# ADSP-2183xW_HPC register map
Vendor: Analog Devices; Series: ADSP-2183xW_HPC; File version: 3.0.3.517
CPU: 
Registers are 32-bit, read-write, reset 0x0 unless marked. A register's access mark holds for its fields unless they carry their own. Offsets are from the block's base; [hi:lo] are bit positions; {n}, {i} and the like mark numbered series.

## PDM0 — Pulse Density Modulation interface block
Base 0x310C9000
Same registers: PDM1 0x310CA000
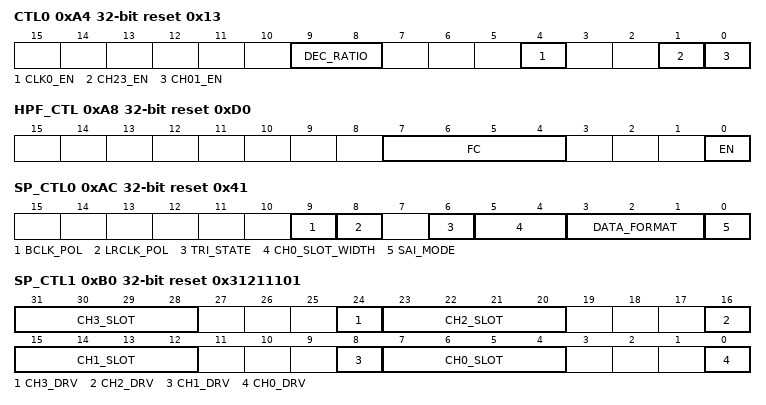
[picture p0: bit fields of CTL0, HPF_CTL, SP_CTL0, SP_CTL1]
0xA4 CTL0 reset 0x13 — PDM Control Register
  [9:8] DEC_RATIO — Decimation Ratio
    0=SIXFOUR (64 times decimation); 1=THREETWO (32 times decimation); 2=ONESIX (16 times decimation)
  [4] CLK0_EN — PDM Clock0 Enable
    0=OFF (PDM_CLK0 output disabled); 1=ON (PDM_CLK0 output enabled)
  [1] CH23_EN — Channels 2/3 (PDM_DAT1) Enable
    0=CH23_OFF (PDM channels 2/3 disabled); 1=CH23_ON (PDM channels 2/3 enabled)
  [0] CH01_EN — Channels 0/1 (PDM_DAT0) Enable
    0=CH01_OFF (PDM channels 0/1 disabled); 1=CH01_ON (PDM channels 0/1 enabled)
0xA8 HPF_CTL reset 0xD0 — High Pass Filter Control Register
  [7:4] FC — High-pass filter cutoff frequency relative to output sample rate
  [0] EN — High-pass filter enable
    0=OFF (High Pass Filter Off); 1=ON (High Pass Filter On)
0xAC SP_CTL0 reset 0x41 — Serial Port Control0 Register
  [9] BCLK_POL — Serial port - selects bclk polarity
    0=NEG (Capture on rising edge); 1=POS (Capture on falling egde)
  [8] LRCLK_POL — Serial port - selects lrclk polarity
    0=NORM (Normal Polarity); 1=INV (Inverted Polarity)
  [6] TRI_STATE — Serial port output - tri-state enable
    0=DISABLE (tri-state disabled); 1=ENABLE (tri-state enabled)
  [5:4] CH0_SLOT_WIDTH — Serial port - selects slot width
    0=THIRTY_TWO (32 BCLK's per slot); 1=SIXTEEN (16 BCLK's per slot); 2=TWENTY_FOUR (24 BCLK's per slot)
  [3:1] DATA_FORMAT — Serial port - selects data format
    0=I2S (Typical I2S mode, delay by 1); 1=LJ (Left Justified,delay by 0); 2=DEL8 (Delay by 8); 3=DEL12 (Delay by 12); 4=DEL16 (Delay by 16)
  [0] SAI_MODE — Serial port - selects SAI mode
    0=STEREO (STEREO (I2S, LJ or RJ)); 1=TDM
0xB0 SP_CTL1 reset 0x31211101 — Serial Port Control1 Register
  [8n+7:8n+4] CH{n}_SLOT (n=0..3) — Serial Port Channel {n} Slot Selection
    0=Map channel to TDM slot 0/I2S Left; 1=Map channel to TDM slot 1/I2S Right; {v}=Map channel to TDM slot {v} (v=2..15)
  [24] CH3_DRV — Serial Port Channel 3 drive select
    0=CH3_NO (Channel will not be driven on serial port); 1=CH3_YES (Channel will be driven on serial port in selected output slot.)
  [16] CH2_DRV — Serial Port Channel 2 drive select
    0=CH2_NO (Channel will not be driven on serial port); 1=CH2_YES (Channel will be driven on serial port in selected output slot.)
  [8] CH1_DRV — Serial Port Channel 1 drive select
    0=NO (Channel will not be driven on serial port); 1=YES (Channel will be driven on serial port in selected output slot.)
  [0] CH0_DRV — Serial Port Channel 0 drive select
    0=CH0_NO (Channel will not be driven on serial port); 1=CH0_YES (Channel will be driven on serial port in selected output slot.)
0xB8 RESET — Software Reset Register
  [0] SOFT wo — Software reset not including register settings
    0=OFF (N/A); 1=ON (Write once to soft reset)

## PKA0 — Public Key Accelerator
Base 0x310D4000
0x00 APTR — PKA Vector_A Address
  [10:0] VALUE range 0x00000000..0x000007FF — Pointer to Vector A
0x04 BPTR — PKA Vector_B Address
  [10:0] VALUE range 0x00000000..0x000007FF — Pointer to Vector B
0x08 CPTR — PKA Vector_C Address
  [10:0] CPTR range 0x00000000..0x000007FF — Pointer to Vector C
0x0C DPTR — PKA Vector_D Address
  [10:0] VALUE range 0x00000000..0x000007FF — Pointer to Vector D
0x10 ALEN — PKA Vector_A Length
  [8:0] VALUE range 0x00000000..0x000001FF — Length of Vector A
0x14 BLEN — PKA Vector_B Length
  [8:0] VALUE range 0x00000000..0x000001FF — Length of Vector B
0x18 SHIFT — PKA Bit Shift Value
  [4:0] VALUE range 0x00000000..0x0000001F — Bits to Shift
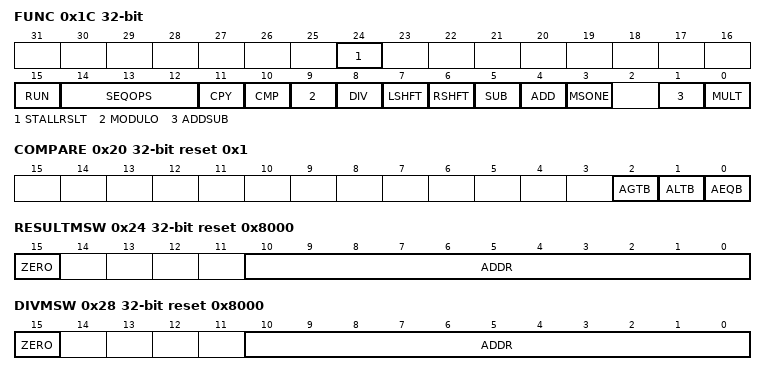
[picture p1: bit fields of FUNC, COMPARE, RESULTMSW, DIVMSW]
0x1C FUNC — PKA Function
  [24] STALLRSLT range 0x00000000..0x00000001 — Stall Result
  [15] RUN range 0x00000000..0x00000001
  [14:12] SEQOPS — Sequencer Operation Select
  [11] CPY range 0x00000000..0x00000001 — Copy
  [10] CMP range 0x00000000..0x00000001 — Perform Compare Operation
  [9] MODULO range 0x00000000..0x00000001 — Perform Modulo Operation
  [8] DIV range 0x00000000..0x00000001 — Perform Divide Operation
  [7] LSHFT range 0x00000000..0x00000001 — Perform Left Shift Operation
  [6] RSHFT range 0x00000000..0x00000001 — Perform Right Shift Operation
  [5] SUB range 0x00000000..0x00000001 — Perform Subtract Operation
  [4] ADD range 0x00000000..0x00000001 — Perform Add Operation
  [3] MSONE range 0x00000000..0x00000001 — Most Significant One
  [1] ADDSUB range 0x00000000..0x00000001 — Perform Combined Add/Subtract Operation
  [0] MULT range 0x00000000..0x00000001 — Perform Multiply Operation
0x20 COMPARE reset 0x1 — PKA Compare Result
  [2] AGTB ro — Vector A is Greater Than Vector B
  [1] ALTB ro — Vector A is Less Than Vector B
  [0] AEQB ro — Vector A is equal to Vector B
0x24 RESULTMSW reset 0x8000 — PKA Most-Significant-Word of Result Vector
  [15] ZERO ro — Result Is Zero
  [10:0] ADDR ro — Address of Most-significant Nonzero Word
0x28 DIVMSW reset 0x8000 — PKA Most-Significant-Word of Divide Remainder
  [15] ZERO ro — Remainder Result Vector is Zeros
  [10:0] ADDR ro — Address of Most-significant Nonzero Word
0x2000 RAM — Start of PKA RAM space
  [31:0] VALUE range 0x00000000..0xFFFFFFFF — First Location in PKA RAM
